# STM32U5A5xx register map
File version: 1.0
Registers are 32-bit, read-write, reset 0x0 unless marked. A register's access mark holds for its fields unless they carry their own. Offsets are from the block's base; [hi:lo] are bit positions; {n}, {i} and the like mark numbered series.

## SYSCFG — System configuration controller
Base 0x46000400
Same registers: SYSCFG_S 0x56000400
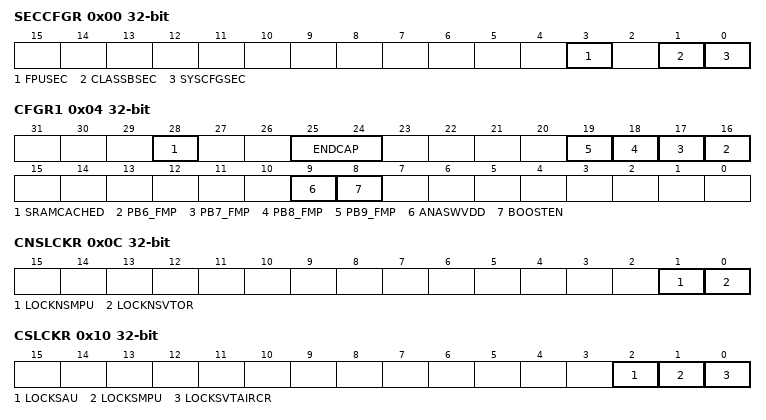
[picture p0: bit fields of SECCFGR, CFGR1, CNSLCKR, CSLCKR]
0x00 SECCFGR — SYSCFG secure configuration register
  [3] FPUSEC — FPU SYSCFG security enable
  [1] CLASSBSEC — ClassB SYSCFG security enable
  [0] SYSCFGSEC — SYSCFG clock control security enable
0x04 CFGR1 — SYSCFG configuration register 1
  [28] SRAMCACHED — Enable the cachability of internal SRAMx by the DCACHE2
  [25:24] ENDCAP — Enable decoupling capacitance on HSPI supply
    0=OFF (Decoupling with no capacitance value on HSPI supply); 1=CAPACITANCE_1_DIV_3 (Decoupling with 1/3 of capacitance value on HSPI supply); 2=CAPACITANCE_2_DIV_3 (Decoupling with 2/3 of capacitance value on HSPI supply); 3=FULL (Decoupling with full capacitance value on HSPI supply)
  [n+10] PB{n}_FMP (n=6..9) — PB{n} Fast mode plus
  [9] ANASWVDD — GPIO analog switch control voltage selection
  [8] BOOSTEN — I/O analog switch voltage booster enable
0x08 FPUIMR — SYSCFG FPU interrupt mask register
  [5:0] FPU_IE — All FPU interrupts enable
0x0C CNSLCKR — SYSCFG CPU non-secure lock register
  [1] LOCKNSMPU — Disable Non-Secure MPU registers writes by SW or debug agent
  [0] LOCKNSVTOR — Disable VTOR_NS register writes by SW or debug agent
0x10 CSLCKR — SYSCFG CPU secure lock register
  [2] LOCKSAU — Disable changes to SAU registers
  [1] LOCKSMPU — Disable changes to the secure MPU registers writes by SW or debug agent
  [0] LOCKSVTAIRCR — Disable changes to the secure vector table address, handling of system faults
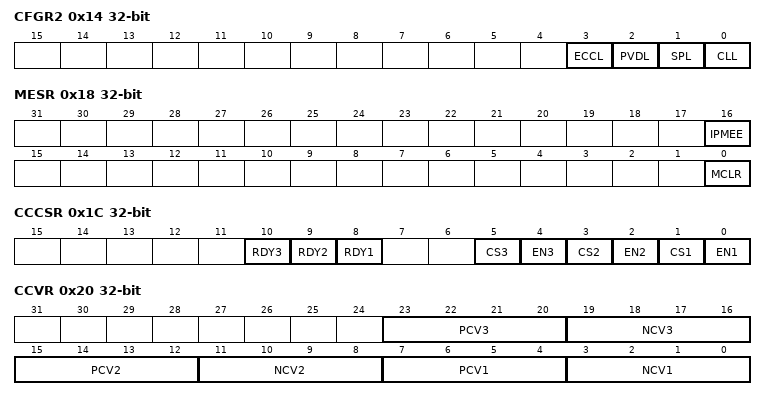
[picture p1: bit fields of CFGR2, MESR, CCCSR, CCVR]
0x14 CFGR2 — SYSCFG configuration register 2
  [3] ECCL — ECC Lock
  [2] PVDL — PVD Lock
  [1] SPL — SRAM ECC Lock
  [0] CLL — Core Lockup Lock
0x18 MESR — SYSCFG Memory Erase Status register
  [16] IPMEE — Status of End of Erase for ICache and PKA RAMs
  [0] MCLR — Status of Erase after Reset
0x1C CCCSR — SYSCFG Conpensaion Cell Control&Status register
  [10] RDY3 — HSPI I/Os compensation cell ready flag
  [9] RDY2 — VDDIO compensation cell ready flag
  [8] RDY1 — VDD compensation cell ready flag
  [5] CS3 — Code selection for HSPI I/Os
  [4] EN3 — Enable compensation cell for HSPI I/Os
  [3] CS2 — Code selection for VDDIO power rail
  [2] EN2 — Enable compensation cell for VDDIO power rail
  [1] CS1 — Code selection for VDD power rail
  [0] EN1 — Enable compensation cell for VDD power rail
0x20 CCVR — SYSCFG Conpensaion Cell value register
  [23:20] PCV3 — PMOS compensation value of the HSPI I/Os supplied by VDD
  [19:16] NCV3 — NMOS compensation value of the HSPI I/Os supplied by VDD
  [15:12] PCV2 — PMOS compensation value for VDDIO Power Rail
  [11:8] NCV2 — NMOS compensation value for VDDIO Power Rail
  [7:4] PCV1 — PMOS compensation value for VDD Power Rail
  [3:0] NCV1 — NMOS compensation value for VDD Power Rail
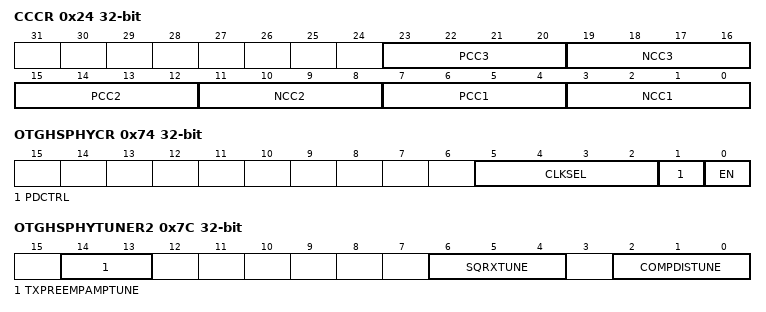
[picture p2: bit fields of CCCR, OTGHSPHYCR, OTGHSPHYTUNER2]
0x24 CCCR — SYSCFG Conpensaion Cell Code register
  [23:20] PCC3 — PMOS compensation code of the HSPI I/Os supplied by VDD
  [19:16] NCC3 — NMOS compensation code of the HSPI I/Os supplied by VDD
  [15:12] PCC2 — PMOS compensation code for VDDIO Power Rail
  [11:8] NCC2 — NMOS compensation code for VDDIO Power Rail
  [7:4] PCC1 — PMOS compensation code for VDD Power Rail
  [3:0] NCC1 — NMOS compensation code for VDD Power Rail
0x2C RSSCMDR — SYSCFG RSS command mode register
  [15:0] RSSCMD — RSS command
0x74 OTGHSPHYCR — SYSCFG USB OTG_HS PHY register
  [5:2] CLKSEL — USB OTG_HS PHY reference clock frequency selection
    3=CLK_16MHZ (Reference clock freqeuncy is 16 Mhz); 8=CLK_19_2MHZ (Reference clock freqeuncy is 19.2 Mhz); 9=CLK_20MHZ (Reference clock freqeuncy is 20 Mhz); 10=CLK_24MHZ (Reference clock freqeuncy is 24 Mhz); 14=CLK_26MHZ; 11=CLK_32MHZ
  [1] PDCTRL — USB OTG_HS PHY common block power-down control
  [0] EN — USB OTG_HS PHY enable
0x7C OTGHSPHYTUNER2 — SYSCFG USB OTG_HS PHY tune register 2
  [14:13] TXPREEMPAMPTUNE — High-speed transmitter preemphasis current control
    0=DISABLED (HS transmitter preemphasis circuit disabled); 1=PREEMP_1X (HS transmitter preemphasis circuit sources 1x preemphasis current); 2=PREEMP_2X (HS transmitter preemphasis circuit sources 2x preemphasis current); 3=PREEMP_3X
  [6:4] SQRXTUNE — Squelch threshold adjustment
    0=SQUELCH_15PERCENT (+15% (recommended value)); 3=SQUELCH_0PERCENT (0% (default value))
  [2:0] COMPDISTUNE — Disconnect threshold adjustment
    2=DISCONNECT_5_9PERCENT (+5.9% (recommended value)); 1=DISCONNECT_0PERCENT (0% (default value))
